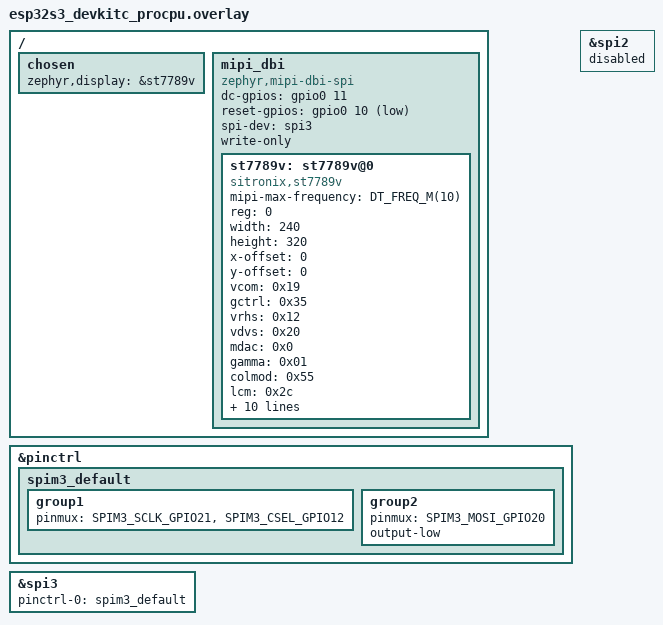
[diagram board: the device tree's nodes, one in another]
/*
 * Copyright (c) 2025 Espressif Systems (Shanghai) Co., Ltd.
 * SPDX-License-Identifier: Apache-2.0
 */

#include <zephyr/dt-bindings/pinctrl/esp32s3-pinctrl.h>

&pinctrl {
	spim3_default: spim3_default {
		group1 {
			pinmux = <SPIM3_SCLK_GPIO21>,
				 <SPIM3_CSEL_GPIO12>;
		};
		group2 {
			pinmux = <SPIM3_MOSI_GPIO20>;
			output-low;
		};
	};
};

/* disable SPI2 as it conflicts with SPI3 pinout */
&spi2 {
	status = "disabled";
};

&spi3 {
	#address-cells = <1>;
	#size-cells = <0>;
	status = "okay";
	pinctrl-0 = <&spim3_default>;
	pinctrl-names = "default";
};

/ {

	chosen {
		zephyr,display = &st7789v;
	};

	mipi_dbi {
		compatible = "zephyr,mipi-dbi-spi";
		dc-gpios = <&gpio0 11 GPIO_ACTIVE_HIGH>;
		reset-gpios = <&gpio0 10 GPIO_ACTIVE_LOW>;
		spi-dev = <&spi3>;
		write-only;
		#address-cells = <1>;
		#size-cells = <0>;
		status = "okay";

		st7789v: st7789v@0 {
			compatible = "sitronix,st7789v";
			mipi-max-frequency = <DT_FREQ_M(10)>;
			reg = <0>;
			width = <240>;
			height = <320>;
			x-offset = <0>;
			y-offset = <0>;
			vcom = <0x19>;
			gctrl = <0x35>;
			vrhs = <0x12>;
			vdvs = <0x20>;
			mdac = <0x0>;
			gamma = <0x01>;
			colmod = <0x55>;
			lcm = <0x2c>;
			porch-param = [0c 0c 00 33 33];
			cmd2en-param = [5a 69 02 01];
			pwctrl1-param = [a4 a1];
			pvgam-param = [D0 04 0D 11 13 2B 3F 54 4C 18 0D 0B 1F 23];
			nvgam-param = [D0 04 0C 11 13 2C 3F 44 51 2F 1F 1F 20 23];
			ram-param = [00 F0];
			rgb-param = [CD 08 14];
			mipi-mode = "MIPI_DBI_MODE_SPI_4WIRE";
		};
	};
};
